# MSP430FR5739 register map
File version: 1.1
CPU: msp430
Registers are 16-bit, access not given, reset 0x0 unless marked. A register's access mark holds for its fields unless they carry their own. Offsets are from the block's base; [hi:lo] are bit positions; {n}, {i} and the like mark numbered series.

## MPY_32__Multiplier__32_Bit_Mode
Base 0x00000000
0x4D0 MPY32L — 32-bit operand 1 - multiply - low word
0x4D2 MPY32H — 32-bit operand 1 - multiply - high word
0x4D4 MPYS32L — 32-bit operand 1 - signed multiply - low word
0x4D6 MPYS32H — 32-bit operand 1 - signed multiply - high word
0x4D8 MAC32L — 32-bit operand 1 - multiply accumulate - low word
0x4DA MAC32H — 32-bit operand 1 - multiply accumulate - high word
0x4DC MACS32L — 32-bit operand 1 - signed multiply accumulate - low word
0x4DE MACS32H — 32-bit operand 1 - signed multiply accumulate - high word
0x4E0 OP2L — 32-bit operand 2 - low word
0x4E2 OP2H — 32-bit operand 2 - high word
0x4E4 RES0 — 32x32-bit result 0 - least significant word
0x4E6 RES1 — 32x32-bit result 1
0x4E8 RES2 — 32x32-bit result 2
0x4EA RES3 — 32x32-bit result 3 - most significant word

## PMM__Power_Management_System
Base 0x00000000
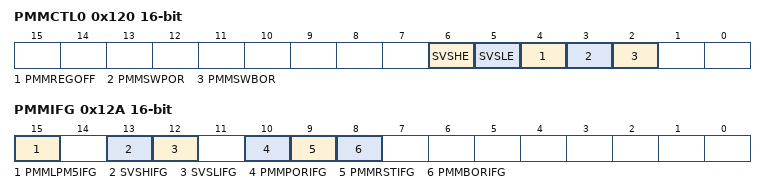
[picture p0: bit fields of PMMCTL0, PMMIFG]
0x120 PMMCTL0 — PMM Control 0
  [6] SVSHE — [6:6] SVS high side enable
  [5] SVSLE — [5:5] SVS low side enable
  [4] PMMREGOFF — [4:4] PMM Turn Regulator off
  [3] PMMSWPOR — [3:3] PMM Software POR
  [2] PMMSWBOR — [2:2] PMM Software BOR
0x12A PMMIFG — PMM Interrupt Flag
  [15] PMMLPM5IFG — [15:15] LPM5 indication Flag
  [13] SVSHIFG — [13:13] SVS low side interrupt flag
  [12] SVSLIFG — [12:12] SVS high side interrupt flag
  [10] PMMPORIFG — [10:10] PMM Software POR interrupt flag
  [9] PMMRSTIFG — [9:9] PMM RESET pin interrupt flag
  [8] PMMBORIFG — [8:8] PMM Software BOR interrupt flag
0x130 PM5CTL0 — PMM Power Mode 5 Control Register 0
  [0] LOCKLPM5 — [0:0] Lock I/O pin configuration upon entry/exit to/from LPM5

## Port_A
Base 0x00000000
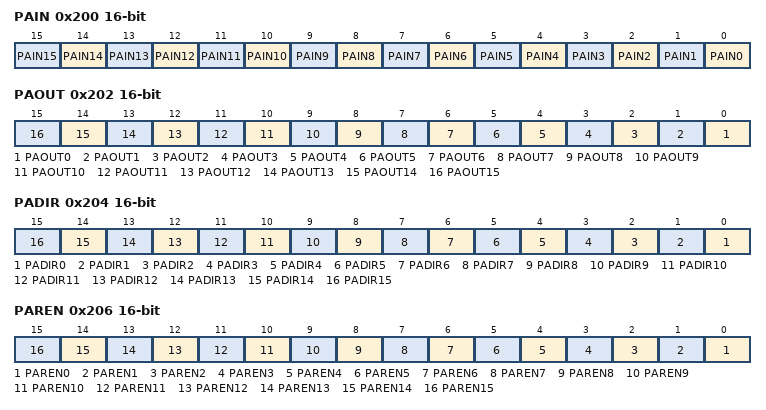
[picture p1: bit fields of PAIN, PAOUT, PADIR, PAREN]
0x200 PAIN — Port A Input
  [n] PAIN{n} (n=0..15) — [{n}:{n}] PAIN{n}
0x202 PAOUT — Port A Output
  [n] PAOUT{n} (n=0..15) — [{n}:{n}] PAOUT{n}
0x204 PADIR — Port A Direction
  [n] PADIR{n} (n=0..15) — [{n}:{n}] PADIR{n}
0x206 PAREN — Port A Resistor Enable
  [n] PAREN{n} (n=0..15) — [{n}:{n}] PAREN{n}
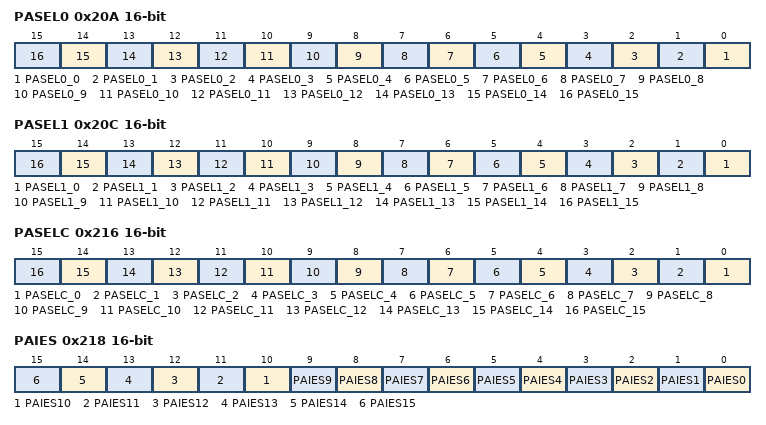
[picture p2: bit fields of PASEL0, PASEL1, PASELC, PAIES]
0x20A PASEL0 — Port A Selection 0
  [n] PASEL0_{n} (n=0..15) — [{n}:{n}] PASEL0_{n}
0x20C PASEL1 — Port A Selection 1
  [n] PASEL1_{n} (n=0..15) — [{n}:{n}] PASEL1_{n}
0x216 PASELC — Port A Complement Selection
  [n] PASELC_{n} (n=0..15) — [{n}:{n}] PASELC_{n}
0x218 PAIES — Port A Interrupt Edge Select
  [n] PAIES{n} (n=0..15) — [{n}:{n}] PAIES{n}
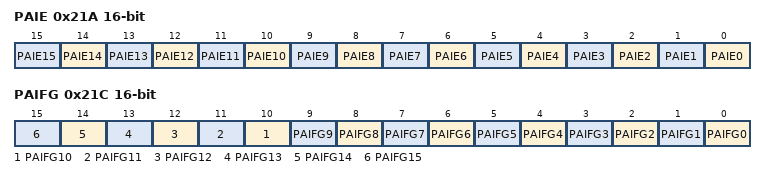
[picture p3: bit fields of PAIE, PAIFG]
0x21A PAIE — Port A Interrupt Enable
  [n] PAIE{n} (n=0..15) — [{n}:{n}] PAIE{n}
0x21C PAIFG — Port A Interrupt Flag
  [n] PAIFG{n} (n=0..15) — [{n}:{n}] PAIFG{n}

## Port_1_2
Base 0x00000000
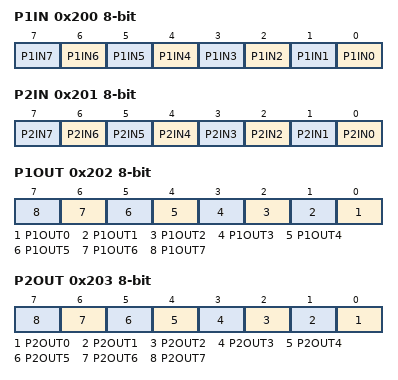
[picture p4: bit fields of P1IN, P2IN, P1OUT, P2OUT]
0x200 P1IN 8-bit — Port 1 Input
  [n] P1IN{n} (n=0..7) — [{n}:{n}] P1IN{n}
0x201 P2IN 8-bit — Port 2 Input
  [n] P2IN{n} (n=0..7) — [{n}:{n}] P2IN{n}
0x202 P1OUT 8-bit — Port 1 Output
  [n] P1OUT{n} (n=0..7) — [{n}:{n}] P1OUT{n}
0x203 P2OUT 8-bit — Port 2 Output
  [n] P2OUT{n} (n=0..7) — [{n}:{n}] P2OUT{n}
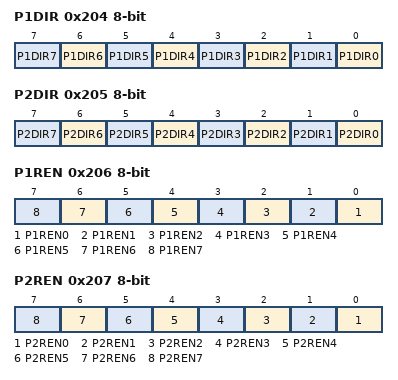
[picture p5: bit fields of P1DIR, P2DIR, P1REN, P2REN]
0x204 P1DIR 8-bit — Port 1 Direction
  [n] P1DIR{n} (n=0..7) — [{n}:{n}] P1DIR{n}
0x205 P2DIR 8-bit — Port 2 Direction
  [n] P2DIR{n} (n=0..7) — [{n}:{n}] P2DIR{n}
0x206 P1REN 8-bit — Port 1 Resistor Enable
  [n] P1REN{n} (n=0..7) — [{n}:{n}] P1REN{n}
0x207 P2REN 8-bit — Port 2 Resistor Enable
  [n] P2REN{n} (n=0..7) — [{n}:{n}] P2REN{n}
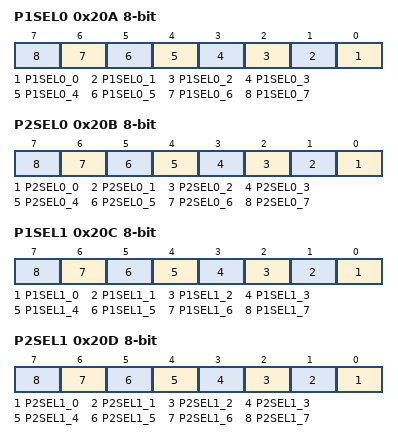
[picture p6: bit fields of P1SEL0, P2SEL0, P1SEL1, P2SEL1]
0x20A P1SEL0 8-bit — Port 1 Selection 0
  [n] P1SEL0_{n} (n=0..7) — [{n}:{n}] P1SEL0_{n}
0x20B P2SEL0 8-bit — Port 2 Selection 0
  [n] P2SEL0_{n} (n=0..7) — [{n}:{n}] P2SEL0_{n}
0x20C P1SEL1 8-bit — Port 1 Selection 1
  [n] P1SEL1_{n} (n=0..7) — [{n}:{n}] P1SEL1_{n}
0x20D P2SEL1 8-bit — Port 2 Selection 1
  [n] P2SEL1_{n} (n=0..7) — [{n}:{n}] P2SEL1_{n}
0x20E P1IV — Port 1 Interrupt Vector Word
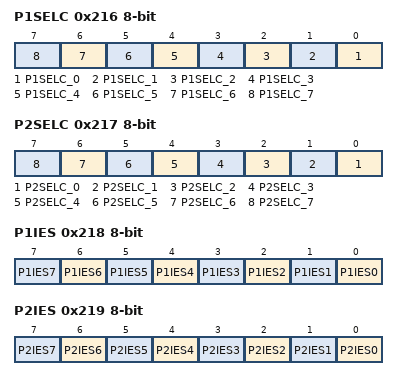
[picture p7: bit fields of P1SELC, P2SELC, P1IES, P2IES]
0x216 P1SELC 8-bit — Port 1 Complement Selection
  [n] P1SELC_{n} (n=0..7) — [{n}:{n}] P1SELC_{n}
0x217 P2SELC 8-bit — Port 2 Complement Selection
  [n] P2SELC_{n} (n=0..7) — [{n}:{n}] P2SELC_{n}
0x218 P1IES 8-bit — Port 1 Interrupt Edge Select
  [n] P1IES{n} (n=0..7) — [{n}:{n}] P1IES{n}
0x219 P2IES 8-bit — Port 2 Interrupt Edge Select
  [n] P2IES{n} (n=0..7) — [{n}:{n}] P2IES{n}
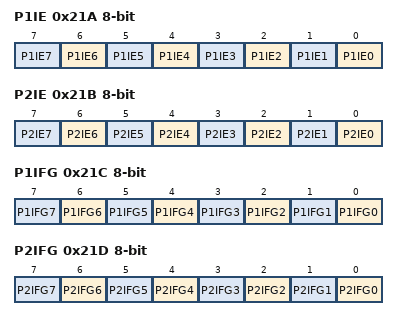
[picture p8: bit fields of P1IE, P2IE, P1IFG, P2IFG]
0x21A P1IE 8-bit — Port 1 Interrupt Enable
  [n] P1IE{n} (n=0..7) — [{n}:{n}] P1IE{n}
0x21B P2IE 8-bit — Port 2 Interrupt Enable
  [n] P2IE{n} (n=0..7) — [{n}:{n}] P2IE{n}
0x21C P1IFG 8-bit — Port 1 Interrupt Flag
  [n] P1IFG{n} (n=0..7) — [{n}:{n}] P1IFG{n}
0x21D P2IFG 8-bit — Port 2 Interrupt Flag
  [n] P2IFG{n} (n=0..7) — [{n}:{n}] P2IFG{n}
0x21E P2IV — Port 2 Interrupt Vector Word
